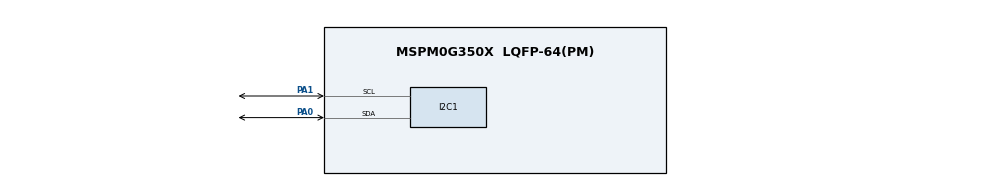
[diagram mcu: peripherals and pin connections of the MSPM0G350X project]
/**
 *
 * @cliArgs --device "MSPM0G350X" --part "Default" --package "LQFP-64(PM)" --product "mspm0_sdk@2.10.00.04"
 * @versions {"tool":"1.28.0+4696"}
 */

/**
 * Import the modules used in this configuration.
 */
const GPIO   = scripting.addModule("/ti/driverlib/GPIO", {}, false);
const GPIO1  = GPIO.addInstance();
const I2C    = scripting.addModule("/ti/driverlib/I2C", {}, false);
const I2C1   = I2C.addInstance();
const SYSCTL = scripting.addModule("/ti/driverlib/SYSCTL");

/**
 * Write custom configuration values to the imported modules.
 */
const divider9       = system.clockTree["UDIV"];
divider9.divideValue = 2;

const mux4       = system.clockTree["EXHFMUX"];
mux4.inputSelect = "EXHFMUX_XTAL";

const mux8       = system.clockTree["HSCLKMUX"];
mux8.inputSelect = "HSCLKMUX_SYSPLL2X";

const mux12       = system.clockTree["SYSPLLMUX"];
mux12.inputSelect = "zSYSPLLMUX_HFCLK";

const pinFunction4     = system.clockTree["HFXT"];
pinFunction4.inputFreq = 40;
pinFunction4.enable    = true;

GPIO1.$name                         = "LED";
GPIO1.port                          = "PORTB";
GPIO1.associatedPins[0].$name       = "PIN_22";
GPIO1.associatedPins[0].assignedPin = "22";

const Board = scripting.addModule("/ti/driverlib/Board", {}, false);

I2C1.$name                           = "I2C_0";
I2C1.basicEnableController           = true;
I2C1.basicControllerStandardBusSpeed = "Fast";
I2C1.peripheral.$assign              = "I2C0";
I2C1.peripheral.sdaPin.$assign       = "PA0";
I2C1.peripheral.sclPin.$assign       = "PA1";
I2C1.sdaPinConfig.$name              = "ti_driverlib_gpio_GPIOPinGeneric0";
I2C1.sclPinConfig.$name              = "ti_driverlib_gpio_GPIOPinGeneric1";

SYSCTL.forceDefaultClkConfig = true;
SYSCTL.clockTreeEn           = true;

const ProjectConfig              = scripting.addModule("/ti/project_config/ProjectConfig", {}, false);
ProjectConfig.migrationCondition = true;

/**
 * Pinmux solution for unlocked pins/peripherals. This ensures that minor changes to the automatic solver in a future
 * version of the tool will not impact the pinmux you originally saw.  These lines can be completely deleted in order to
 * re-solve from scratch.
 */
pinFunction4.peripheral.$suggestSolution           = "SYSCTL";
pinFunction4.peripheral.hfxInPin.$suggestSolution  = "PA5";
pinFunction4.peripheral.hfxOutPin.$suggestSolution = "PA6";
GPIO1.associatedPins[0].pin.$suggestSolution       = "PB22";
Board.peripheral.$suggestSolution                  = "DEBUGSS";
Board.peripheral.swclkPin.$suggestSolution         = "PA20";
Board.peripheral.swdioPin.$suggestSolution         = "PA19";
